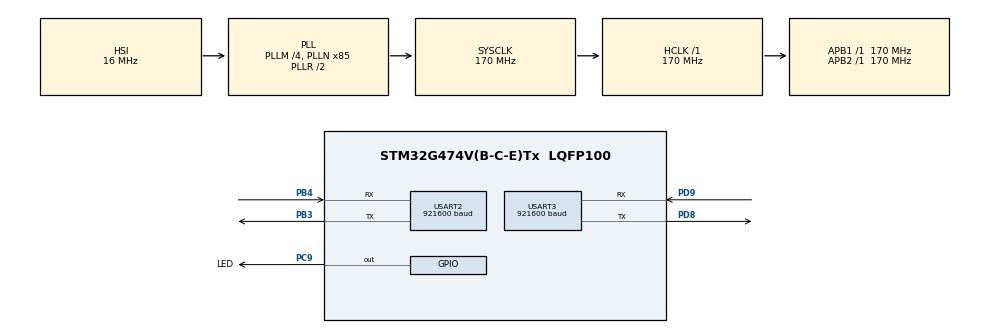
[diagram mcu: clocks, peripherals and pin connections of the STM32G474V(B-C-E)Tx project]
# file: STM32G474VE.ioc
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CRC.CRCLength=CRC_POLYLENGTH_16B
CRC.DefaultInitValueUse=DEFAULT_INIT_VALUE_DISABLE
CRC.DefaultPolynomialUse=DEFAULT_POLYNOMIAL_DISABLE
CRC.GeneratingPolynomial=X12+X5+X0
CRC.InitValue=0x0000
Dma.Request0=USART2_RX
Dma.USART2_RX.0.Direction=DMA_PERIPH_TO_MEMORY
Dma.USART2_RX.0.EventEnable=DISABLE
Dma.USART2_RX.0.Instance=DMA1_Channel1
Dma.USART2_RX.0.MemDataAlignment=DMA_MDATAALIGN_BYTE
Dma.USART2_RX.0.MemInc=DMA_MINC_ENABLE
Dma.USART2_RX.0.Mode=DMA_NORMAL
Dma.USART2_RX.0.PeriphDataAlignment=DMA_PDATAALIGN_BYTE
Dma.USART2_RX.0.PeriphInc=DMA_PINC_DISABLE
Dma.USART2_RX.0.Polarity=HAL_DMAMUX_REQ_GEN_RISING
Dma.USART2_RX.0.Priority=DMA_PRIORITY_LOW
Dma.USART2_RX.0.RequestNumber=1
Dma.USART2_RX.0.SignalID=NONE
Dma.USART2_RX.0.SyncEnable=DISABLE
Dma.USART2_RX.0.SyncPolarity=HAL_DMAMUX_SYNC_NO_EVENT
Dma.USART2_RX.0.SyncRequestNumber=1
Dma.USART2_RX.0.SyncSignalID=NONE
IWDG.Prescaler=IWDG_PRESCALER_64
Mcu.Family=STM32G4
Mcu.Name=STM32G474V(B-C-E)Tx
Mcu.Package=LQFP100
NVIC.DMA1_Channel1_IRQn=true\:0\:0\:false\:false\:true\:false\:true\:true
NVIC.PriorityGroup=NVIC_PRIORITYGROUP_4
NVIC.TIM20_UP_IRQn=true\:0\:0\:false\:false\:true\:true\:true\:true
NVIC.USART2_IRQn=true\:0\:0\:false\:false\:true\:true\:true\:true
PA9.Signal=USART1_TX
PB3.Mode=Asynchronous
PB3.Signal=USART2_TX
PB4.Mode=Asynchronous
PB4.Signal=USART2_RX
PC9.GPIO_Label=LED
PC9.PinState=GPIO_PIN_SET
PC9.Signal=GPIO_Output
PD8.Mode=Asynchronous
PD8.Signal=USART3_TX
PD9.Mode=Asynchronous
PD9.Signal=USART3_RX
ProjectManager.HeapSize=0x8000
ProjectManager.StackSize=0x8000
ProjectManager.TargetToolchain=MDK-ARM V5.32
RCC.ADC12Freq_Value=170000000
RCC.ADC345Freq_Value=170000000
RCC.AHBFreq_Value=170000000
RCC.APB1Freq_Value=170000000
RCC.APB1TimFreq_Value=170000000
RCC.APB2Freq_Value=170000000
RCC.APB2TimFreq_Value=170000000
RCC.CortexFreq_Value=170000000
RCC.EXTERNAL_CLOCK_VALUE=12288000
RCC.HCLKFreq_Value=170000000
RCC.HSE_VALUE=8000000
RCC.HSI48_VALUE=48000000
RCC.HSI_VALUE=16000000
RCC.LSE_VALUE=32768
RCC.PLLM=RCC_PLLM_DIV4
RCC.PLLN=85
RCC.SYSCLKFreq_VALUE=170000000
RCC.SYSCLKSource=RCC_SYSCLKSOURCE_PLLCLK
RCC.USBFreq_Value=170000000
RCC.VCOOutputFreq_Value=340000000
TIM20.PeriodNoDither=10000-1
TIM20.Prescaler=1700-1
USART2.BaudRate=921600
USART2.VirtualMode-Asynchronous=VM_ASYNC
USART3.BaudRate=921600
USART3.VirtualMode-Asynchronous=VM_ASYNC
VP_CRC_VS_CRC.Mode=CRC_Activate
VP_IWDG_VS_IWDG.Mode=IWDG_Activate
VP_SYS_VS_DBSignals.Mode=DisableDeadBatterySignals
VP_TIM20_VS_ClockSourceINT.Mode=Internal
board=custom

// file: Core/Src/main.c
/* USER CODE BEGIN Header */
/**
  ******************************************************************************
  * @file           : main.c
  * @brief          : Main program body
  ******************************************************************************
  * @attention
  *
  * Copyright (c) 2025 STMicroelectronics.
  * All rights reserved.
  *
  * This software is licensed under terms that can be found in the LICENSE file
  * in the root directory of this software component.
  * If no LICENSE file comes with this software, it is provided AS-IS.
  *
  ******************************************************************************
  */
/* USER CODE END Header */
#include "main.h"

/* USER CODE BEGIN Includes */
#include "task.h"
/* USER CODE END Includes */

CRC_HandleTypeDef hcrc;

IWDG_HandleTypeDef hiwdg;

TIM_HandleTypeDef htim20;

UART_HandleTypeDef huart2;
UART_HandleTypeDef huart3;
DMA_HandleTypeDef hdma_usart2_rx;

void SystemClock_Config(void);
static void MX_GPIO_Init(void);
static void MX_DMA_Init(void);
static void MX_USART2_UART_Init(void);
static void MX_USART3_UART_Init(void);
static void MX_CRC_Init(void);
static void MX_TIM20_Init(void);
static void MX_IWDG_Init(void);

int main(void)
{

  /* MCU Configuration--------------------------------------------------------*/

  /* Reset of all peripherals, Initializes the Flash interface and the Systick. */
  HAL_Init();

  /* Configure the system clock */
  SystemClock_Config();

  /* Initialize all configured peripherals */
  MX_GPIO_Init();
  MX_DMA_Init();
  MX_USART2_UART_Init();
  MX_USART3_UART_Init();
  MX_CRC_Init();
  MX_TIM20_Init();
  MX_IWDG_Init();

  /* Infinite loop */
  /* USER CODE BEGIN WHILE */
  while (1)
  {
      task_run();
    /* USER CODE END WHILE */

  }
}

void SystemClock_Config(void)
{
  RCC_OscInitTypeDef RCC_OscInitStruct = {0};
  RCC_ClkInitTypeDef RCC_ClkInitStruct = {0};

  /** Configure the main internal regulator output voltage
  */
  HAL_PWREx_ControlVoltageScaling(PWR_REGULATOR_VOLTAGE_SCALE1_BOOST);

  /** Initializes the RCC Oscillators according to the specified parameters
  * in the RCC_OscInitTypeDef structure.
  */
  RCC_OscInitStruct.OscillatorType = RCC_OSCILLATORTYPE_HSI|RCC_OSCILLATORTYPE_LSI;
  RCC_OscInitStruct.HSIState = RCC_HSI_ON;
  RCC_OscInitStruct.HSICalibrationValue = RCC_HSICALIBRATION_DEFAULT;
  RCC_OscInitStruct.LSIState = RCC_LSI_ON;
  RCC_OscInitStruct.PLL.PLLState = RCC_PLL_ON;
  RCC_OscInitStruct.PLL.PLLSource = RCC_PLLSOURCE_HSI;
  RCC_OscInitStruct.PLL.PLLM = RCC_PLLM_DIV4;
  RCC_OscInitStruct.PLL.PLLN = 85;
  RCC_OscInitStruct.PLL.PLLP = RCC_PLLP_DIV2;
  RCC_OscInitStruct.PLL.PLLQ = RCC_PLLQ_DIV2;
  RCC_OscInitStruct.PLL.PLLR = RCC_PLLR_DIV2;
  if (HAL_RCC_OscConfig(&RCC_OscInitStruct) != HAL_OK)
  {
    Error_Handler();
  }

  /** Initializes the CPU, AHB and APB buses clocks
  */
  RCC_ClkInitStruct.ClockType = RCC_CLOCKTYPE_HCLK|RCC_CLOCKTYPE_SYSCLK
                              |RCC_CLOCKTYPE_PCLK1|RCC_CLOCKTYPE_PCLK2;
  RCC_ClkInitStruct.SYSCLKSource = RCC_SYSCLKSOURCE_PLLCLK;
  RCC_ClkInitStruct.AHBCLKDivider = RCC_SYSCLK_DIV1;
  RCC_ClkInitStruct.APB1CLKDivider = RCC_HCLK_DIV1;
  RCC_ClkInitStruct.APB2CLKDivider = RCC_HCLK_DIV1;

  if (HAL_RCC_ClockConfig(&RCC_ClkInitStruct, FLASH_LATENCY_4) != HAL_OK)
  {
    Error_Handler();
  }
}

static void MX_CRC_Init(void)
{

  hcrc.Instance = CRC;
  hcrc.Init.DefaultPolynomialUse = DEFAULT_POLYNOMIAL_DISABLE;
  hcrc.Init.DefaultInitValueUse = DEFAULT_INIT_VALUE_DISABLE;
  hcrc.Init.GeneratingPolynomial = 4129;
  hcrc.Init.CRCLength = CRC_POLYLENGTH_16B;
  hcrc.Init.InitValue = 0x0000;
  hcrc.Init.InputDataInversionMode = CRC_INPUTDATA_INVERSION_NONE;
  hcrc.Init.OutputDataInversionMode = CRC_OUTPUTDATA_INVERSION_DISABLE;
  hcrc.InputDataFormat = CRC_INPUTDATA_FORMAT_BYTES;
  if (HAL_CRC_Init(&hcrc) != HAL_OK)
  {
    Error_Handler();
  }

}

static void MX_IWDG_Init(void)
{

  hiwdg.Instance = IWDG;
  hiwdg.Init.Prescaler = IWDG_PRESCALER_64;
  hiwdg.Init.Window = 4095;
  hiwdg.Init.Reload = 4095;
  if (HAL_IWDG_Init(&hiwdg) != HAL_OK)
  {
    Error_Handler();
  }

}

static void MX_TIM20_Init(void)
{

  TIM_ClockConfigTypeDef sClockSourceConfig = {0};
  TIM_MasterConfigTypeDef sMasterConfig = {0};

  htim20.Instance = TIM20;
  htim20.Init.Prescaler = 1700-1;
  htim20.Init.CounterMode = TIM_COUNTERMODE_UP;
  htim20.Init.Period = 9999;
  htim20.Init.ClockDivision = TIM_CLOCKDIVISION_DIV1;
  htim20.Init.RepetitionCounter = 0;
  htim20.Init.AutoReloadPreload = TIM_AUTORELOAD_PRELOAD_DISABLE;
  if (HAL_TIM_Base_Init(&htim20) != HAL_OK)
  {
    Error_Handler();
  }
  sClockSourceConfig.ClockSource = TIM_CLOCKSOURCE_INTERNAL;
  if (HAL_TIM_ConfigClockSource(&htim20, &sClockSourceConfig) != HAL_OK)
  {
    Error_Handler();
  }
  sMasterConfig.MasterOutputTrigger = TIM_TRGO_RESET;
  sMasterConfig.MasterOutputTrigger2 = TIM_TRGO2_RESET;
  sMasterConfig.MasterSlaveMode = TIM_MASTERSLAVEMODE_DISABLE;
  if (HAL_TIMEx_MasterConfigSynchronization(&htim20, &sMasterConfig) != HAL_OK)
  {
    Error_Handler();
  }

}

static void MX_USART2_UART_Init(void)
{

  huart2.Instance = USART2;
  huart2.Init.BaudRate = 921600;
  huart2.Init.WordLength = UART_WORDLENGTH_8B;
  huart2.Init.StopBits = UART_STOPBITS_1;
  huart2.Init.Parity = UART_PARITY_NONE;
  huart2.Init.Mode = UART_MODE_TX_RX;
  huart2.Init.HwFlowCtl = UART_HWCONTROL_NONE;
  huart2.Init.OverSampling = UART_OVERSAMPLING_16;
  huart2.Init.OneBitSampling = UART_ONE_BIT_SAMPLE_DISABLE;
  huart2.Init.ClockPrescaler = UART_PRESCALER_DIV1;
  huart2.AdvancedInit.AdvFeatureInit = UART_ADVFEATURE_NO_INIT;
  if (HAL_UART_Init(&huart2) != HAL_OK)
  {
    Error_Handler();
  }
  if (HAL_UARTEx_SetTxFifoThreshold(&huart2, UART_TXFIFO_THRESHOLD_1_8) != HAL_OK)
  {
    Error_Handler();
  }
  if (HAL_UARTEx_SetRxFifoThreshold(&huart2, UART_RXFIFO_THRESHOLD_1_8) != HAL_OK)
  {
    Error_Handler();
  }
  if (HAL_UARTEx_DisableFifoMode(&huart2) != HAL_OK)
  {
    Error_Handler();
  }

}

static void MX_USART3_UART_Init(void)
{

  huart3.Instance = USART3;
  huart3.Init.BaudRate = 921600;
  huart3.Init.WordLength = UART_WORDLENGTH_8B;
  huart3.Init.StopBits = UART_STOPBITS_1;
  huart3.Init.Parity = UART_PARITY_NONE;
  huart3.Init.Mode = UART_MODE_TX_RX;
  huart3.Init.HwFlowCtl = UART_HWCONTROL_NONE;
  huart3.Init.OverSampling = UART_OVERSAMPLING_16;
  huart3.Init.OneBitSampling = UART_ONE_BIT_SAMPLE_DISABLE;
  huart3.Init.ClockPrescaler = UART_PRESCALER_DIV1;
  huart3.AdvancedInit.AdvFeatureInit = UART_ADVFEATURE_NO_INIT;
  if (HAL_UART_Init(&huart3) != HAL_OK)
  {
    Error_Handler();
  }
  if (HAL_UARTEx_SetTxFifoThreshold(&huart3, UART_TXFIFO_THRESHOLD_1_8) != HAL_OK)
  {
    Error_Handler();
  }
  if (HAL_UARTEx_SetRxFifoThreshold(&huart3, UART_RXFIFO_THRESHOLD_1_8) != HAL_OK)
  {
    Error_Handler();
  }
  if (HAL_UARTEx_DisableFifoMode(&huart3) != HAL_OK)
  {
    Error_Handler();
  }

}

static void MX_DMA_Init(void)
{

  /* DMA controller clock enable */
  __HAL_RCC_DMAMUX1_CLK_ENABLE();
  __HAL_RCC_DMA1_CLK_ENABLE();

  /* DMA interrupt init */
  /* DMA1_Channel1_IRQn interrupt configuration */
  HAL_NVIC_SetPriority(DMA1_Channel1_IRQn, 0, 0);
  HAL_NVIC_EnableIRQ(DMA1_Channel1_IRQn);

}

static void MX_GPIO_Init(void)
{
  GPIO_InitTypeDef GPIO_InitStruct = {0};

  /* GPIO Ports Clock Enable */
  __HAL_RCC_GPIOD_CLK_ENABLE();
  __HAL_RCC_GPIOC_CLK_ENABLE();
  __HAL_RCC_GPIOA_CLK_ENABLE();
  __HAL_RCC_GPIOB_CLK_ENABLE();

  /*Configure GPIO pin Output Level */
  HAL_GPIO_WritePin(LED_GPIO_Port, LED_Pin, GPIO_PIN_SET);

  /*Configure GPIO pin : LED_Pin */
  GPIO_InitStruct.Pin = LED_Pin;
  GPIO_InitStruct.Mode = GPIO_MODE_OUTPUT_PP;
  GPIO_InitStruct.Pull = GPIO_NOPULL;
  GPIO_InitStruct.Speed = GPIO_SPEED_FREQ_LOW;
  HAL_GPIO_Init(LED_GPIO_Port, &GPIO_InitStruct);

  /*Configure GPIO pin : PA9 */
  GPIO_InitStruct.Pin = GPIO_PIN_9;
  GPIO_InitStruct.Mode = GPIO_MODE_AF_PP;
  GPIO_InitStruct.Pull = GPIO_NOPULL;
  GPIO_InitStruct.Speed = GPIO_SPEED_FREQ_LOW;
  GPIO_InitStruct.Alternate = GPIO_AF7_USART1;
  HAL_GPIO_Init(GPIOA, &GPIO_InitStruct);

}

void Error_Handler(void)
{
  __disable_irq();
  while (1)
  {
  }
}
